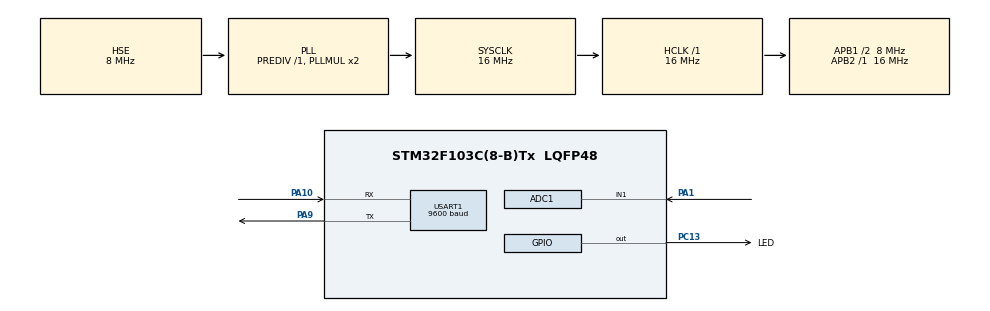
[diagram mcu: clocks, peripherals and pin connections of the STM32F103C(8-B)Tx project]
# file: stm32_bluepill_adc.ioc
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ADC1.Channel-1\#ChannelRegularConversion=ADC_CHANNEL_1
ADC1.Channel-2\#ChannelRegularConversion=ADC_CHANNEL_1
ADC1.ContinuousConvMode=ENABLE
ADC1.NbrOfConversion=2
ADC1.NbrOfConversionFlag=1
ADC1.Rank-1\#ChannelRegularConversion=1
ADC1.Rank-2\#ChannelRegularConversion=2
ADC1.SamplingTime-1\#ChannelRegularConversion=ADC_SAMPLETIME_1CYCLE_5
ADC1.SamplingTime-2\#ChannelRegularConversion=ADC_SAMPLETIME_1CYCLE_5
ADC1.master=1
Mcu.Family=STM32F1
Mcu.Name=STM32F103C(8-B)Tx
Mcu.Package=LQFP48
NVIC.PriorityGroup=NVIC_PRIORITYGROUP_4
PA1.GPIO_Mode=GPIO_MODE_ANALOG
PA1.Signal=ADCx_IN1
PA10.Mode=Asynchronous
PA10.Signal=USART1_RX
PA13.Mode=Serial_Wire
PA13.Signal=SYS_JTMS-SWDIO
PA14.Mode=Serial_Wire
PA14.Signal=SYS_JTCK-SWCLK
PA9.Mode=Asynchronous
PA9.Signal=USART1_TX
PC13-TAMPER-RTC.GPIO_Label=LED
PC13-TAMPER-RTC.GPIO_Speed=GPIO_SPEED_FREQ_HIGH
PC13-TAMPER-RTC.Signal=GPIO_Output
PD0-OSC_IN.Mode=HSE-External-Oscillator
PD0-OSC_IN.Signal=RCC_OSC_IN
PD1-OSC_OUT.Mode=HSE-External-Oscillator
PD1-OSC_OUT.Signal=RCC_OSC_OUT
ProjectManager.HeapSize=0x200
ProjectManager.StackSize=0x400
ProjectManager.TargetToolchain=STM32CubeIDE
RCC.AHBFreq_Value=16000000
RCC.APB1CLKDivider=RCC_HCLK_DIV2
RCC.APB1Freq_Value=8000000
RCC.APB1TimFreq_Value=16000000
RCC.APB2Freq_Value=16000000
RCC.APB2TimFreq_Value=16000000
RCC.HCLKFreq_Value=16000000
RCC.PLLSourceVirtual=RCC_PLLSOURCE_HSE
RCC.SYSCLKFreq_VALUE=16000000
RCC.SYSCLKSource=RCC_SYSCLKSOURCE_PLLCLK
RCC.USBFreq_Value=16000000
SH.ADCx_IN1.0=ADC1_IN1,IN1
USART1.BaudRate=9600
USART1.VirtualMode=VM_ASYNC
board=custom

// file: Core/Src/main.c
/* USER CODE BEGIN Header */
/**
  ******************************************************************************
  * @file           : main.c
  * @brief          : Main program body
  ******************************************************************************
  * @attention
  *
  * <h2><center>&copy; Copyright (c) 2020 STMicroelectronics.
  * All rights reserved.</center></h2>
  *
  * This software component is licensed by ST under BSD 3-Clause license,
  * the "License"; You may not use this file except in compliance with the
  * License. You may obtain a copy of the License at:
  *                        opensource.org/licenses/BSD-3-Clause
  *
  ******************************************************************************
  */
/* USER CODE END Header */
#include "main.h"

ADC_HandleTypeDef hadc1;

UART_HandleTypeDef huart1;

void SystemClock_Config(void);
static void MX_GPIO_Init(void);
static void MX_USART1_UART_Init(void);
static void MX_ADC1_Init(void);

/* USER CODE BEGIN 0 */
void send_string(char* s)
{
	HAL_UART_Transmit(&huart1, (uint8_t*)s, strlen(s), 1000);
}

void send_char(char c)
{
	HAL_UART_Transmit(&huart1, (uint8_t*)&c, 1, 1000);
}

int __io_putchar(int ch)
{
	send_char(ch);
	return ch;
}
/* USER CODE END 0 */

int main(void)
{

  /* MCU Configuration--------------------------------------------------------*/

  /* Reset of all peripherals, Initializes the Flash interface and the Systick. */
  HAL_Init();

  /* Configure the system clock */
  SystemClock_Config();

  /* Initialize all configured peripherals */
  MX_GPIO_Init();
  MX_USART1_UART_Init();
  MX_ADC1_Init();
  /* USER CODE BEGIN 2 */
  HAL_ADC_Start(&hadc1);
  /* USER CODE END 2 */

  /* Infinite loop */
  while (1)
  {
	  if(HAL_ADC_PollForConversion(&hadc1, 10) == HAL_OK)
	  {
		  uint32_t value = HAL_ADC_GetValue(&hadc1);
		  float result = 3.3 * 1000 * (float)value / 4095 ;
		  printf("adc = %d mV \n", (int)result);
		  HAL_ADC_Start(&hadc1);
	  }
	  HAL_Delay(500);
  }
}

void SystemClock_Config(void)
{
  RCC_OscInitTypeDef RCC_OscInitStruct = {0};
  RCC_ClkInitTypeDef RCC_ClkInitStruct = {0};
  RCC_PeriphCLKInitTypeDef PeriphClkInit = {0};

  /** Initializes the RCC Oscillators according to the specified parameters
  * in the RCC_OscInitTypeDef structure.
  */
  RCC_OscInitStruct.OscillatorType = RCC_OSCILLATORTYPE_HSE;
  RCC_OscInitStruct.HSEState = RCC_HSE_ON;
  RCC_OscInitStruct.HSEPredivValue = RCC_HSE_PREDIV_DIV1;
  RCC_OscInitStruct.HSIState = RCC_HSI_ON;
  RCC_OscInitStruct.PLL.PLLState = RCC_PLL_ON;
  RCC_OscInitStruct.PLL.PLLSource = RCC_PLLSOURCE_HSE;
  RCC_OscInitStruct.PLL.PLLMUL = RCC_PLL_MUL2;
  if (HAL_RCC_OscConfig(&RCC_OscInitStruct) != HAL_OK)
  {
    Error_Handler();
  }
  /** Initializes the CPU, AHB and APB buses clocks
  */
  RCC_ClkInitStruct.ClockType = RCC_CLOCKTYPE_HCLK|RCC_CLOCKTYPE_SYSCLK
                              |RCC_CLOCKTYPE_PCLK1|RCC_CLOCKTYPE_PCLK2;
  RCC_ClkInitStruct.SYSCLKSource = RCC_SYSCLKSOURCE_PLLCLK;
  RCC_ClkInitStruct.AHBCLKDivider = RCC_SYSCLK_DIV1;
  RCC_ClkInitStruct.APB1CLKDivider = RCC_HCLK_DIV2;
  RCC_ClkInitStruct.APB2CLKDivider = RCC_HCLK_DIV1;

  if (HAL_RCC_ClockConfig(&RCC_ClkInitStruct, FLASH_LATENCY_0) != HAL_OK)
  {
    Error_Handler();
  }
  PeriphClkInit.PeriphClockSelection = RCC_PERIPHCLK_ADC;
  PeriphClkInit.AdcClockSelection = RCC_ADCPCLK2_DIV2;
  if (HAL_RCCEx_PeriphCLKConfig(&PeriphClkInit) != HAL_OK)
  {
    Error_Handler();
  }
}

static void MX_ADC1_Init(void)
{

  ADC_ChannelConfTypeDef sConfig = {0};

  /** Common config
  */
  hadc1.Instance = ADC1;
  hadc1.Init.ScanConvMode = ADC_SCAN_ENABLE;
  hadc1.Init.ContinuousConvMode = ENABLE;
  hadc1.Init.DiscontinuousConvMode = DISABLE;
  hadc1.Init.ExternalTrigConv = ADC_SOFTWARE_START;
  hadc1.Init.DataAlign = ADC_DATAALIGN_RIGHT;
  hadc1.Init.NbrOfConversion = 2;
  if (HAL_ADC_Init(&hadc1) != HAL_OK)
  {
    Error_Handler();
  }
  /** Configure Regular Channel
  */
  sConfig.Channel = ADC_CHANNEL_1;
  sConfig.Rank = ADC_REGULAR_RANK_1;
  sConfig.SamplingTime = ADC_SAMPLETIME_1CYCLE_5;
  if (HAL_ADC_ConfigChannel(&hadc1, &sConfig) != HAL_OK)
  {
    Error_Handler();
  }
  /** Configure Regular Channel
  */
  sConfig.Rank = ADC_REGULAR_RANK_2;
  if (HAL_ADC_ConfigChannel(&hadc1, &sConfig) != HAL_OK)
  {
    Error_Handler();
  }

}

static void MX_USART1_UART_Init(void)
{

  huart1.Instance = USART1;
  huart1.Init.BaudRate = 9600;
  huart1.Init.WordLength = UART_WORDLENGTH_8B;
  huart1.Init.StopBits = UART_STOPBITS_1;
  huart1.Init.Parity = UART_PARITY_NONE;
  huart1.Init.Mode = UART_MODE_TX_RX;
  huart1.Init.HwFlowCtl = UART_HWCONTROL_NONE;
  huart1.Init.OverSampling = UART_OVERSAMPLING_16;
  if (HAL_UART_Init(&huart1) != HAL_OK)
  {
    Error_Handler();
  }

}

static void MX_GPIO_Init(void)
{
  GPIO_InitTypeDef GPIO_InitStruct = {0};

  /* GPIO Ports Clock Enable */
  __HAL_RCC_GPIOC_CLK_ENABLE();
  __HAL_RCC_GPIOD_CLK_ENABLE();
  __HAL_RCC_GPIOA_CLK_ENABLE();

  /*Configure GPIO pin Output Level */
  HAL_GPIO_WritePin(LED_GPIO_Port, LED_Pin, GPIO_PIN_RESET);

  /*Configure GPIO pin : LED_Pin */
  GPIO_InitStruct.Pin = LED_Pin;
  GPIO_InitStruct.Mode = GPIO_MODE_OUTPUT_PP;
  GPIO_InitStruct.Pull = GPIO_NOPULL;
  GPIO_InitStruct.Speed = GPIO_SPEED_FREQ_HIGH;
  HAL_GPIO_Init(LED_GPIO_Port, &GPIO_InitStruct);

}

void Error_Handler(void)
{
}

/************************ (C) COPYRIGHT STMicroelectronics *****END OF FILE****/
